# MKL36Z4 register map
Vendor: Freescale Semiconductor, Inc.; File version: 1.6
CPU: CM0PLUS r0p0, little endian, no MPU, no FPU, 0x2 interrupt priority bits, 0x0 interrupts
Registers are 32-bit, read-write, reset 0x0 unless marked. A register's access mark holds for its fields unless they carry their own. Offsets are from the block's base; [hi:lo] are bit positions; {n}, {i} and the like mark numbered series; 'fields as' and 'values as' point back to an identical list.

## DMAMUX0 — DMA channel multiplexor
Base 0x40021000; register names take the prefix DMAMUX0_
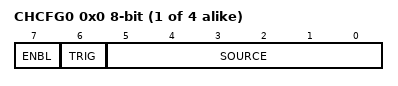
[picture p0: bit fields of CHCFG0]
{0x0+i} CHCFG{i} 8-bit (i=0..3) — Channel Configuration register
  [7] ENBL — DMA Channel Enable
    0=DMA channel is disabled. This mode is primarily used during configuration of the DMAMux. The DMA has separate channel enables/disables, which should be used to disable or reconfigure a DMA channel.; 1=DMA channel is enabled
  [6] TRIG — DMA Channel Trigger Enable
    0=Triggering is disabled. If triggering is disabled and ENBL is set, the DMA Channel will simply route the specified source to the DMA channel. (Normal mode); 1=Triggering is enabled. If triggering is enabled and ENBL is set, the DMAMUX is in Periodic Trigger mode.
  [5:0] SOURCE — DMA Channel Source (Slot)
    0=Disable_Signal; 2=UART0_Rx_Signal; 3=UART0_Tx_Signal; 4=UART1_Rx_Signal; 5=UART1_Tx_Signal; 6=UART2_Rx_Signal; 7=UART2_Tx_Signal; 14=I2S0_Rx_Signal; 15=I2S0_Tx_Signal; 16=SPI0_Rx_Signal; 17=SPI0_Tx_Signal; 18=SPI1_Rx_Signal; 19=SPI1_Tx_Signal; 22=I2C0_Signal; 23=I2C1_Signal; {v}=TPM0_Channel{v-24}_Signal (v=24..29); 32=TPM1_Channel0_Signal; 33=TPM1_Channel1_Signal; 34=TPM2_Channel0_Signal; 35=TPM2_Channel1_Signal; 40=ADC0_Signal; 42=CMP0_Signal; 45=DAC0_Signal; 49=PortA_Signal; 51=PortC_Signal; 52=PortD_Signal; 54=TPM0_Overflow_Signal; 55=TPM1_Overflow_Signal; 56=TPM2_Overflow_Signal; 57=TSI_Signal; {v}=AlwaysOn{v}_Signal (v=60..63)

## PIT — Periodic Interrupt Timer
Base 0x40037000; register names take the prefix PIT_
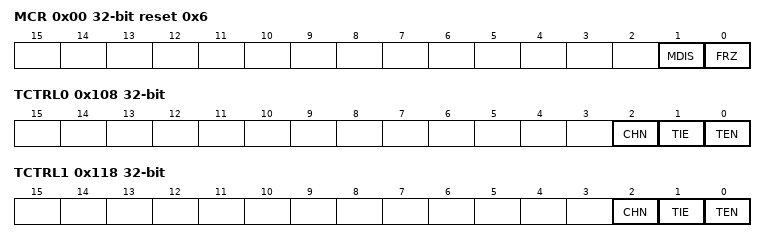
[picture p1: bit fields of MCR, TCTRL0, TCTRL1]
0x00 MCR reset 0x6 — PIT Module Control Register
  [1] MDIS — Module Disable - (PIT section)
    0=Clock for standard PIT timers is enabled; 1=Clock for standard PIT timers is disabled
  [0] FRZ — Freeze
    0=Timers continue to run in Debug mode; 1=Timers are stopped in Debug mode
0xE0 LTMR64H ro — PIT Upper Lifetime Timer Register
  [31:0] LTH — Life Timer value
0xE4 LTMR64L ro — PIT Lower Lifetime Timer Register
  [31:0] LTL — Life Timer value
0x100 LDVAL0 — Timer Load Value Register
  [31:0] TSV — Timer Start Value
0x104 CVAL0 ro — Current Timer Value Register
  [31:0] TVL — Current Timer Value
0x108 TCTRL0 — Timer Control Register
  [2] CHN — Chain Mode
    0=Timer is not chained; 1=Timer is chained to previous timer. For example, for Channel 2, if this field is set, Timer 2 is chained to Timer 1.
  [1] TIE — Timer Interrupt Enable
    0=Interrupt requests from Timer n are disabled; 1=Interrupt will be requested whenever TIF is set
  [0] TEN — Timer Enable
    0=Timer n is disabled; 1=Timer n is enabled
0x10C TFLG0 — Timer Flag Register
  [0] TIF — Timer Interrupt Flag
    0=Timeout has not yet occurred; 1=Timeout has occurred
0x110 LDVAL1 — Timer Load Value Register
  [31:0] TSV — Timer Start Value
0x114 CVAL1 ro — Current Timer Value Register
  [31:0] TVL — Current Timer Value
0x118 TCTRL1 — Timer Control Register
  fields as TCTRL0
0x11C TFLG1 — Timer Flag Register
  fields as TFLG0

## TPM0 — Timer/PWM Module
Base 0x40038000; register names take the prefix TPM0_
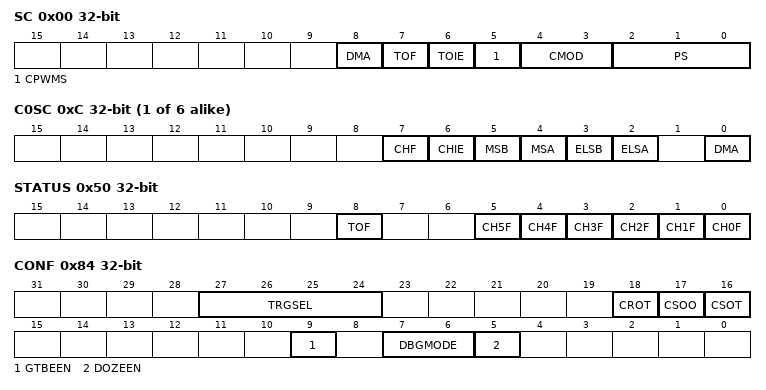
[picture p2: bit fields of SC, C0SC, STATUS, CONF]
0x00 SC — Status and Control
  [8] DMA — DMA Enable
    0=Disables DMA transfers; 1=Enables DMA transfers
  [7] TOF — Timer Overflow Flag
    0=TPM counter has not overflowed; 1=TPM counter has overflowed
  [6] TOIE — Timer Overflow Interrupt Enable
    0=Disable TOF interrupts. Use software polling or DMA request.; 1=Enable TOF interrupts. An interrupt is generated when TOF equals one.
  [5] CPWMS — Center-Aligned PWM Select
    0=TPM counter operates in up counting mode; 1=TPM counter operates in up-down counting mode
  [4:3] CMOD — Clock Mode Selection
    0=TPM counter is disabled; 1=TPM counter increments on every TPM counter clock; 2=TPM counter increments on rising edge of TPM_EXTCLK synchronized to the TPM counter clock
  [2:0] PS — Prescale Factor Selection
    0=Divide by 1; 1=Divide by 2; 2=Divide by 4; 3=Divide by 8; 4=Divide by 16; 5=Divide by 32; 6=Divide by 64; 7=Divide by 128
0x04 CNT — Counter
  [15:0] COUNT — Counter value
0x08 MOD reset 0xFFFF — Modulo
  [15:0] MOD — Modulo value
{0xC+8i} C{i}SC (i=0..5) — Channel (n) Status and Control
  [7] CHF — Channel Flag
    0=No channel event has occurred; 1=A channel event has occurred
  [6] CHIE — Channel Interrupt Enable
    0=Disable channel interrupts; 1=Enable channel interrupts
  [5] MSB — Channel Mode Select
  [4] MSA — Channel Mode Select
  [3] ELSB — Edge or Level Select
  [2] ELSA — Edge or Level Select
  [0] DMA — DMA Enable
    0=Disable DMA transfers; 1=Enable DMA transfers
{0x10+8i} C{i}V (i=0..5) — Channel (n) Value
  [15:0] VAL — Channel Value
0x50 STATUS — Capture and Compare Status
  [8] TOF — Timer Overflow Flag
    values as SC.TOF
  [n] CH{n}F (n=0..5) — Channel {n} Flag
    values as C0SC.CHF
0x84 CONF — Configuration
  [27:24] TRGSEL — Trigger Select
  [18] CROT — Counter Reload On Trigger
    0=Counter is not reloaded due to a rising edge on the selected input trigger; 1=Counter is reloaded when a rising edge is detected on the selected input trigger
  [17] CSOO — Counter Stop On Overflow
    0=TPM counter continues incrementing or decrementing after overflow; 1=TPM counter stops incrementing or decrementing after overflow
  [16] CSOT — Counter Start on Trigger
    0=TPM counter starts to increment immediately, once it is enabled; 1=TPM counter only starts to increment when it a rising edge on the selected input trigger is detected, after it has been enabled or after it has stopped due to overflow
  [9] GTBEEN — Global time base enable
    0=All channels use the internally generated TPM counter as their timebase; 1=All channels use an externally generated global timebase as their timebase
  [7:6] DBGMODE — Debug Mode
    0=TPM counter is paused and does not increment during debug mode. Trigger inputs and input capture events are also ignored.; 3=TPM counter continues in debug mode
  [5] DOZEEN — Doze Enable
    0=Internal TPM counter continues in Doze mode; 1=Internal TPM counter is paused and does not increment during Doze mode. Trigger inputs and input capture events are also ignored.

## TPM1 — Timer/PWM Module
Base 0x40039000; register names take the prefix TPM1_
Registers as TPM0, without C{n}SC (n=2..5), C{n}V (n=2..5).

## TPM2 — Timer/PWM Module
Base 0x4003A000; register names take the prefix TPM2_
Registers as TPM0, without C{n}SC (n=2..5), C{n}V (n=2..5).
